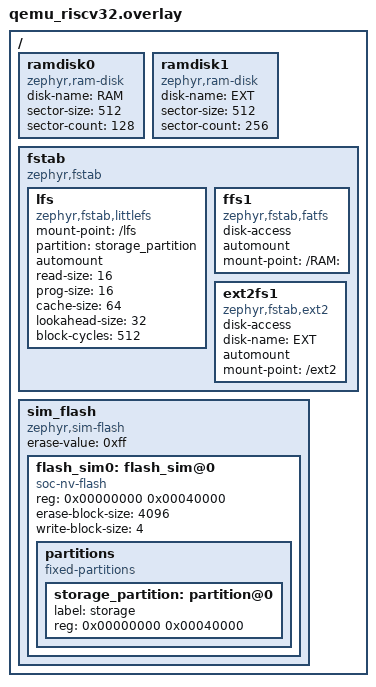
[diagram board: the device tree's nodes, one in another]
/ {
	ramdisk0 {
		compatible = "zephyr,ram-disk";
		disk-name = "RAM";
		sector-size = <512>;
		sector-count = <128>;
	};

	ramdisk1 {
		compatible = "zephyr,ram-disk";
		disk-name = "EXT";
		sector-size = <512>;
		sector-count = <256>;
	};

	fstab {
		compatible = "zephyr,fstab";

		lfs: lfs {
			compatible = "zephyr,fstab,littlefs";
			mount-point = "/lfs";
			partition = <&storage_partition>;
			automount;
			read-size = <16>;
			prog-size = <16>;
			cache-size = <64>;
			lookahead-size = <32>;
			block-cycles = <512>;
		};

		ffs1: ffs1 {
			compatible = "zephyr,fstab,fatfs";
			disk-access;
			automount;
			mount-point = "/RAM:";
		};

		ext2fs1: ext2fs1 {
			compatible = "zephyr,fstab,ext2";
			disk-access;
			disk-name = "EXT";
			automount;
			mount-point = "/ext2";
		};
	};

	sim_flash: sim_flash {
		compatible = "zephyr,sim-flash";
		#address-cells = <1>;
		#size-cells = <1>;
		erase-value = <0xff>;

		flash_sim0: flash_sim@0 {
			compatible = "soc-nv-flash";
			reg = <0x00000000 0x00040000>;

			erase-block-size = <4096>;
			write-block-size = <4>;

			partitions {
				compatible = "fixed-partitions";
				#address-cells = <1>;
				#size-cells = <1>;

				storage_partition: partition@0 {
					label = "storage";
					reg = <0x00000000 0x00040000>;
				};
			};
		};
	};
};
